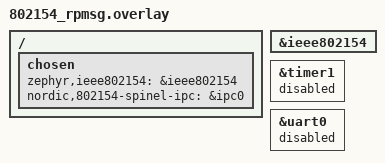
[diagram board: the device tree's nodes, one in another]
/ {
    chosen {
        zephyr,ieee802154 = &ieee802154;
        nordic,802154-spinel-ipc = &ipc0;
    };
};

&ieee802154 {
    status = "okay";
};

&timer1 {
    status = "disabled";
};

&uart0 {
    status = "disabled";
};
